AUTOSAR XML (schema 00047)
package /Components
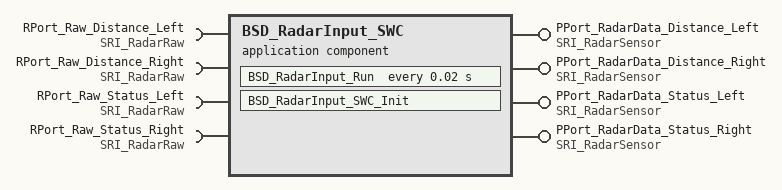
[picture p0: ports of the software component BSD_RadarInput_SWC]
  application sw component type BSD_RadarInput_SWC
    4 x require port, all with required-interface=SRI_RadarRaw:
      RPort_Raw_Distance_Left: nonqueued-receiver-com-spec{data-element=Raw_Distance, init-value=0}
      RPort_Raw_Distance_Right: nonqueued-receiver-com-spec{data-element=Raw_Distance, init-value=0}
      RPort_Raw_Status_Left: nonqueued-receiver-com-spec{data-element=Raw_Status, init-value=0}
      RPort_Raw_Status_Right: nonqueued-receiver-com-spec{data-element=Raw_Status, init-value=0}
    4 x provide port, all with provided-interface=SRI_RadarSensor:
      PPort_RadarData_Distance_Left: nonqueued-sender-com-spec{data-element=Distance, init-value=0}
      PPort_RadarData_Distance_Right: nonqueued-sender-com-spec{data-element=Distance, init-value=0}
      PPort_RadarData_Status_Left: nonqueued-sender-com-spec{data-element=Status, init-value=0}
      PPort_RadarData_Status_Right: nonqueued-sender-com-spec{data-element=Status, init-value=0}
    behavior BSD_RadarInput_SWC_IB: handle-termination-and-restart=NO-SUPPORT
      timing event TE_RadarInput_20ms: start-on-event=BSD_RadarInput_Run, period=0.02
      runnable BSD_RadarInput_Run
        data-read-access:
          4 x access:
            IN_RPort_Raw_Distance_Left_Raw_Distance: accessed-variable=RPort_Raw_Distance_Left.Raw_Distance
            IN_RPort_Raw_Distance_Right_Raw_Distance: accessed-variable=RPort_Raw_Distance_Right.Raw_Distance
            IN_RPort_Raw_Status_Left_Raw_Status: accessed-variable=RPort_Raw_Status_Left.Raw_Status
            IN_RPort_Raw_Status_Right_Raw_Status: accessed-variable=RPort_Raw_Status_Right.Raw_Status
        data-write-access:
          4 x access:
            OUT_PPort_RadarData_Distance_Left_Distance: accessed-variable=PPort_RadarData_Distance_Left.Distance
            OUT_PPort_RadarData_Distance_Right_Distance: accessed-variable=PPort_RadarData_Distance_Right.Distance
            OUT_PPort_RadarData_Status_Left_Status: accessed-variable=PPort_RadarData_Status_Left.Status
            OUT_PPort_RadarData_Status_Right_Status: accessed-variable=PPort_RadarData_Status_Right.Status
      runnable BSD_RadarInput_SWC_Init
